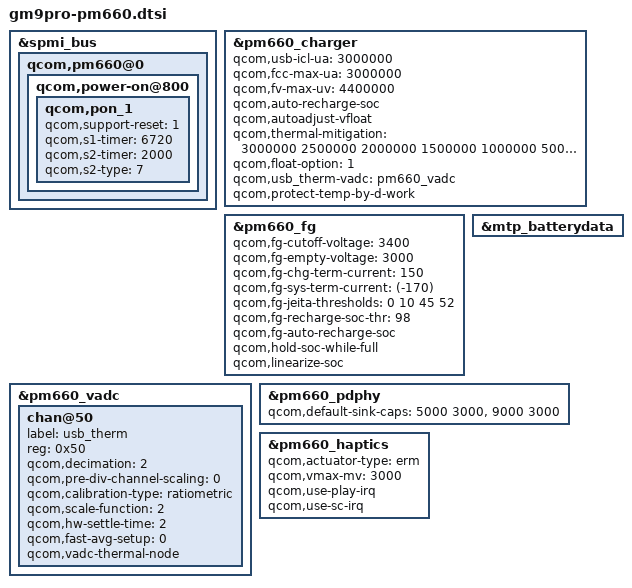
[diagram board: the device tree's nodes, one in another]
/* Copyright (c) 2019, The Linux Foundation. All rights reserved.
 *
 * This program is free software; you can redistribute it and/or modify
 * it under the terms of the GNU General Public License version 2 and
 * only version 2 as published by the Free Software Foundation.
 *
 * This program is distributed in the hope that it will be useful,
 * but WITHOUT ANY WARRANTY; without even the implied warranty of
 * MERCHANTABILITY or FITNESS FOR A PARTICULAR PURPOSE.  See the
 * GNU General Public License for more details.
 */

/* msm-pm660.dtsi common diff */

&spmi_bus {
	qcom,pm660@0 {
		qcom,power-on@800 {
			qcom,pon_1 {
				qcom,support-reset = <1>;
				qcom,s1-timer = <6720>;
				qcom,s2-timer = <2000>;
				qcom,s2-type = <7>;
			};
		};
	};
};

&pm660_charger {
	qcom,usb-icl-ua = <3000000>;
	qcom,fcc-max-ua = <3000000>;
	qcom,fv-max-uv = <4400000>;
	qcom,auto-recharge-soc;
	qcom,autoadjust-vfloat;
	qcom,thermal-mitigation = <3000000 2500000 2000000 1500000 1000000 500000>;
	qcom,float-option = <1>;
	qcom,usb_therm-vadc = <&pm660_vadc>;
	qcom,protect-temp-by-d-work;
};

&pm660_fg {
	qcom,fg-cutoff-voltage = <3400>;
	qcom,fg-empty-voltage = <3000>;
	qcom,fg-chg-term-current = <150>;
	qcom,fg-sys-term-current = <(-170)>;
	qcom,fg-jeita-thresholds = <0 10 45 52>;
	qcom,fg-recharge-soc-thr = <98>;
	qcom,fg-auto-recharge-soc;
	qcom,hold-soc-while-full;
	qcom,linearize-soc;
};

&mtp_batterydata {
		#include "fg-gen3-batterydata-l9500atl_3800mah.dtsi"
};

&pm660_vadc{
	chan@50 {
		label = "usb_therm";
		reg = <0x50>;
		qcom,decimation = <2>;
		qcom,pre-div-channel-scaling = <0>;
		qcom,calibration-type = "ratiometric";
		qcom,scale-function = <2>;
		qcom,hw-settle-time = <2>;
		qcom,fast-avg-setup = <0>;
		qcom,vadc-thermal-node;
	};
 };

 &pm660_pdphy {
	qcom,default-sink-caps = <5000 3000>, /* 5V @ 3A */
							 <9000 3000>; /* 9V @ 3A */
};

&pm660_haptics {
	/delete-property/ qcom,int-pwm-freq-khz;
	/delete-property/ qcom,brake-pattern;
	/delete-property/ qcom,lra-high-z;
	/delete-property/ qcom,lra-auto-res-mode;
	/delete-property/ qcom,lra-calibrate-at-eop;
	/delete-property/ qcom,correct-lra-drive-freq;
	/delete-property/ qcom,en-brake;

	qcom,actuator-type = "erm";
	qcom,vmax-mv = <3000>;
	qcom,use-play-irq;
	qcom,use-sc-irq;
};
